AUTOSAR XML (schema 00046)
package /ComponentTypes
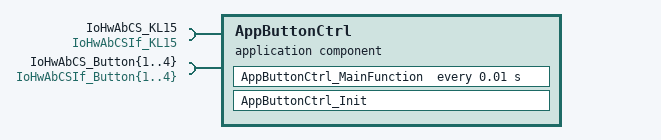
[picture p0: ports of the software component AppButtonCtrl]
  application sw component type AppButtonCtrl
    5 x require port:
      IoHwAbCS_KL15: client-com-spec=IoHwAbOp_KL15_Read, required-interface=IoHwAbCSIf_KL15
      IoHwAbCS_Button{1..4}: client-com-spec=IoHwAbOp_Button{1..4}_Read, required-interface=IoHwAbCSIf_Button{1..4}
    behavior AppButtonCtrl_InternalBehavior
      timing event TMT_AppButtonCtrl_MainFunction: start-on-event=AppButtonCtrl_MainFunction, period=0.01
      init event AppButtonCtrl_InitEvent: start-on-event=AppButtonCtrl_Init
      runnable AppButtonCtrl_MainFunction
        5 x sync call:
          SC_IoHwAbCS_Button{1..4}_IoHwAbOp_Button{1..4}_Read: operation=IoHwAbCS_Button{1..4}.IoHwAbOp_Button{1..4}_Read
          SC_IoHwAbCS_KL15_IoHwAbOp_KL15_Read: operation=IoHwAbCS_KL15.IoHwAbOp_KL15_Read
      runnable AppButtonCtrl_Init
  swc implementation AppButtonCtrl_Implementation: behavior=AppButtonCtrl_InternalBehavior
